# STM32L496xx register map
File version: 1.0
Registers are 32-bit, read-write, reset 0x0 unless marked. A register's access mark holds for its fields unless they carry their own. Offsets are from the block's base; [hi:lo] are bit positions; lines under a group give offsets from that group; {n}, {i} and the like mark numbered series; 'fields as' and 'values as' point back to an identical list.

## CRC — CRC calculation unit
Base 0x40023000
0x00 DR — CRC Data register
  [31:0] DR — Data register bits
0x04 IDR 8-bit — CRC Independent data register
  [7:0] IDR — General-purpose 8-bit data register bits
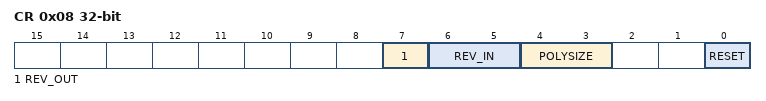
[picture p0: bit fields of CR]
0x08 CR — CRC Control register
  [7] REV_OUT — REV_OUT Reverse Output Data bits
    0=NONE (Output Data bit order not affected); 1=BIT (Output Data bit reversal done by bit)
  [6:5] REV_IN — REV_IN Reverse Input Data bits
    0=NONE (Input Data bit order not affected); 1=BYTE (Input Data bit reversal done by byte); 2=HALFWORD (Input Data bit reversal done by half-word); 3=WORD (Input Data bit reversal done by word)
  [4:3] POLYSIZE — Polynomial size bits
    0=POLYLENGTH_32B (32 bits Polynomial size); 1=POLYLENGTH_16B (16 bits Polynomial size); 2=POLYLENGTH_8B (8 bits Polynomial size); 3=POLYLENGTH_7B (7 bits Polynomial size)
  [0] RESET — RESET the CRC computation unit bit
0x10 INIT — Initial CRC value register
  [31:0] INIT — Initial CRC value bits
0x14 POL — CRC polynomial register
  [31:0] POL — Coefficients of the polynomial

## TSC — Touch Sensing Controller (TSC)
Base 0x40024000
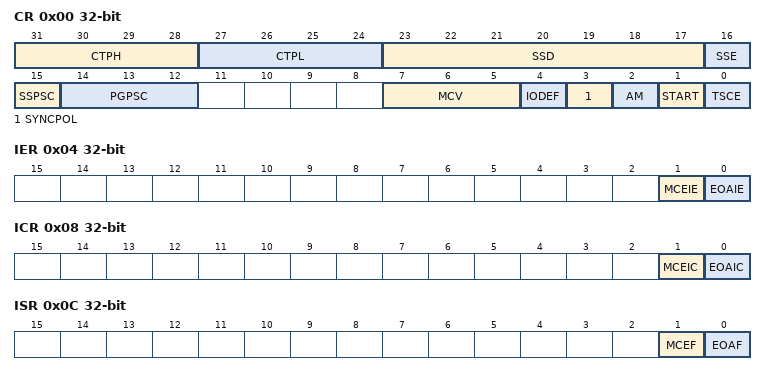
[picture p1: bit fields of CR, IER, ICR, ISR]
0x00 CR — TSC control register
  [31:28] CTPH — CTPH[3:0] bits (Charge Transfer pulse high)
  [27:24] CTPL — CTPL[3:0] bits (Charge Transfer pulse low)
  [23:17] SSD — SSD[6:0] bits (Spread Spectrum Deviation)
  [16] SSE — Spread Spectrum Enable
  [15] SSPSC — Spread Spectrum Prescaler
  [14:12] PGPSC — PGPSC[2:0] bits (Pulse Generator Prescaler)
  [7:5] MCV — MCV[2:0] bits (Max Count Value)
  [4] IODEF — IO default mode
  [3] SYNCPOL — Synchronization pin polarity
  [2] AM — Acquisition mode
  [1] START — Start acquisition
  [0] TSCE — Touch sensing controller enable
0x04 IER — TSC interrupt enable register
  [1] MCEIE — Max count error interrupt enable
  [0] EOAIE — End of acquisition interrupt enable
0x08 ICR — TSC interrupt clear register
  [1] MCEIC — Max count error interrupt clear
  [0] EOAIC — End of acquisition interrupt clear
0x0C ISR — TSC interrupt status register
  [1] MCEF — Max count error flag
  [0] EOAF — End of acquisition flag
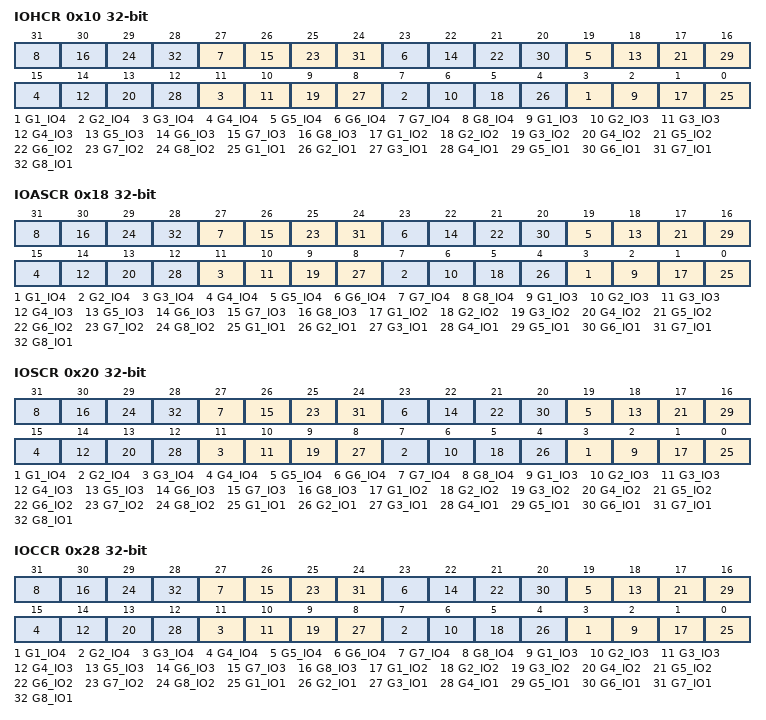
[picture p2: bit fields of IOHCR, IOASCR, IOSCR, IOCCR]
0x10 IOHCR — TSC I/O hysteresis control register
  [4n-1] G{n}_IO4 (n=1..8) — GROUP{n}_IO4 schmitt trigger hysteresis mode
  [4n-2] G{n}_IO3 (n=1..8) — GROUP{n}_IO3 schmitt trigger hysteresis mode
  [4n-3] G{n}_IO2 (n=1..8) — GROUP{n}_IO2 schmitt trigger hysteresis mode
  [4n-4] G{n}_IO1 (n=1..8) — GROUP{n}_IO1 schmitt trigger hysteresis mode
0x18 IOASCR — TSC I/O analog switch control register
  [4n-1] G{n}_IO4 (n=1..8) — GROUP{n}_IO4 analog switch enable
  [4n-2] G{n}_IO3 (n=1..8) — GROUP{n}_IO3 analog switch enable
  [4n-3] G{n}_IO2 (n=1..8) — GROUP{n}_IO2 analog switch enable
  [4n-4] G{n}_IO1 (n=1..8) — GROUP{n}_IO1 analog switch enable
0x20 IOSCR — TSC I/O sampling control register
  [4n-1] G{n}_IO4 (n=1..8) — GROUP{n}_IO4 sampling mode
  [4n-2] G{n}_IO3 (n=1..8) — GROUP{n}_IO3 sampling mode
  [4n-3] G{n}_IO2 (n=1..8) — GROUP{n}_IO2 sampling mode
  [4n-4] G{n}_IO1 (n=1..8) — GROUP{n}_IO1 sampling mode
0x28 IOCCR — TSC I/O channel control register
  [4n-1] G{n}_IO4 (n=1..8) — GROUP{n}_IO4 channel mode
  [4n-2] G{n}_IO3 (n=1..8) — GROUP{n}_IO3 channel mode
  [4n-3] G{n}_IO2 (n=1..8) — GROUP{n}_IO2 channel mode
  [4n-4] G{n}_IO1 (n=1..8) — GROUP{n}_IO1 channel mode
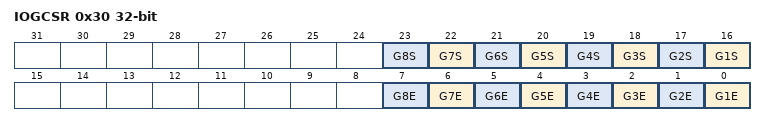
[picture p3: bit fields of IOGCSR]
0x30 IOGCSR — TSC I/O group control status register
  [n+15] G{n}S (n=1..8) — Analog IO GROUP{n} status
  [n-1] G{n}E (n=1..8) — Analog IO GROUP{n} enable
{0x30+4i} IOG{i}CR (i=1..8) — TSC I/O group x counter register
  [13:0] CNT — CNT[13:0] bits (Counter value)

## DMA2D — DMA2D Controller
Base 0x4002B000
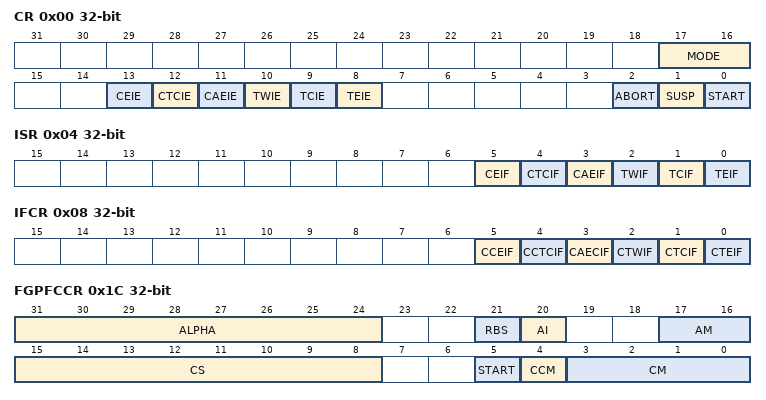
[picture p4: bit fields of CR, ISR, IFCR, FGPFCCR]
0x00 CR — DMA2D Control Register
  [17:16] MODE — DMA2D Mode[1:0]
    0=M2M (DMA2D memory to memory transfer mode); 1=M2M_PFC (DMA2D memory to memory with pixel format conversion transfer mode); 2=M2M_BLEND (DMA2D memory to memory with blending transfer mode); 3=R2M (DMA2D register to memory transfer mode)
  [13] CEIE — Configuration Error Interrupt Enable
  [12] CTCIE — CLUT Transfer Complete Interrupt Enable
  [11] CAEIE — CLUT Access Error Interrupt Enable
  [10] TWIE — Transfer Watermark Interrupt Enable
  [9] TCIE — Transfer Complete Interrupt Enable
  [8] TEIE — Transfer Error Interrupt Enable
  [2] ABORT — Abort transfer
  [1] SUSP — Suspend transfer
  [0] START — Start transfer
0x04 ISR — DMA2D Interrupt Status Register
  [5] CEIF — Configuration Error Interrupt Flag
  [4] CTCIF — CLUT Transfer Complete Interrupt Flag
  [3] CAEIF — CLUT Access Error Interrupt Flag
  [2] TWIF — Transfer Watermark Interrupt Flag
  [1] TCIF — Transfer Complete Interrupt Flag
  [0] TEIF — Transfer Error Interrupt Flag
0x08 IFCR — DMA2D Interrupt Flag Clear Register
  [5] CCEIF — Clears Configuration Error Interrupt Flag
  [4] CCTCIF — Clears CLUT Transfer Complete Interrupt Flag
  [3] CAECIF — Clears CLUT Access Error Interrupt Flag
  [2] CTWIF — Clears Transfer Watermark Interrupt Flag
  [1] CTCIF — Clears Transfer Complete Interrupt Flag
  [0] CTEIF — Clears Transfer Error Interrupt Flag
0x0C FGMAR — DMA2D Foreground Memory Address Register
  [31:0] MA — Memory Address
0x10 FGOR — DMA2D Foreground
  [13:0] LO — Line Offset
0x14 BGMAR — DMA2D Background Memory Address Register
  [31:0] MA — Memory Address
0x18 BGOR — DMA2D Background
  [13:0] LO — Line Offset
0x1C FGPFCCR — DMA2D Foreground PFC Control Register
  [31:24] ALPHA — Alpha value
  [21] RBS — Red Blue Swap
    0=REGULAR (RGB or ARGB); 1=SWAP (BGR or ABGR)
  [20] AI — Alpha Inverted
    0=REGULAR (Regular alpha); 1=INVERTED (Inverted alpha)
  [17:16] AM — Alpha mode AM[1:0]
    0=NO_MODIF (No modification of the alpha channel value); 1=REPLACE; 2=COMBINE
  [15:8] CS — CLUT size
  [5] START
  [4] CCM — CLUT Color mode
    0=ARGB8888; 1=RGB888
  [3:0] CM — Input color mode CM[3:0]
    0=ARGB8888; 1=RGB888; 2=RGB565; 3=ARGB1555; 4=ARGB4444; 5=L8; 6=AL44; 7=AL88; 8=L4; 9=A8; 10=A4
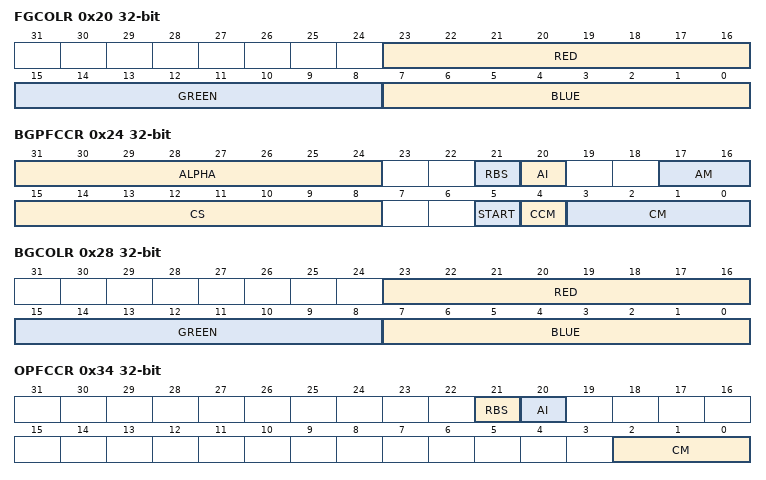
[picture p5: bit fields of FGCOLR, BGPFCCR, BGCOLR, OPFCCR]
0x20 FGCOLR — DMA2D Foreground Color Register
  [23:16] RED — Red Value
  [15:8] GREEN — Green Value
  [7:0] BLUE — Blue Value
0x24 BGPFCCR — DMA2D Background PFC Control Register
  fields as FGPFCCR
0x28 BGCOLR — DMA2D Background Color Register
  fields as FGCOLR
0x2C FGCMAR — DMA2D Foreground CLUT Memory Address Register
  [31:0] MA — Memory Address
0x30 BGCMAR — DMA2D Background CLUT Memory Address Register
  [31:0] MA — Memory Address
0x34 OPFCCR — DMA2D Output PFC Control Register
  [21] RBS — Red Blue Swap
    0=REGULAR (RGB or ARGB); 1=SWAP (BGR or ABGR)
  [20] AI — Alpha Inverted
    0=REGULAR (Regular alpha); 1=INVERTED (Inverted alpha)
  [2:0] CM — Color mode CM[2:0]
    0=ARGB8888; 1=RGB888; 2=RGB565; 3=ARGB1555; 4=ARGB4444
0x38 OCOLR — DMA2D Output Color Register
0x3C OMAR — DMA2D Output Memory Address Register
  [31:0] MA — Memory Address
0x40 OOR — DMA2D Output
  [13:0] LO — Line Offset
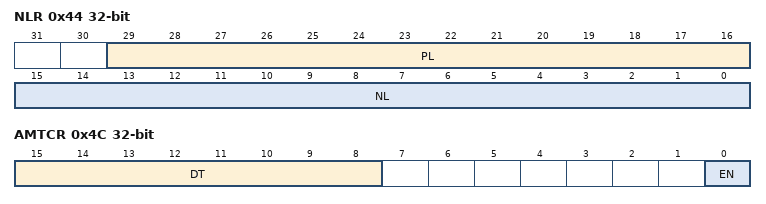
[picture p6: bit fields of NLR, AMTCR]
0x44 NLR — DMA2D Number of Line Register
  [29:16] PL — Pixel per Lines
  [15:0] NL — Number of Lines
0x48 LWR — DMA2D Line Watermark Register
  [15:0] LW — Line Watermark
0x4C AMTCR — DMA2D AHB Master Timer Configuration Register
  [15:8] DT — Dead Time
  [0] EN — Enable
{0x400+4i} FGCLUT[{i}] (i=0..255)
{0x800+4i} BGCLUT[{i}] (i=0..255)
